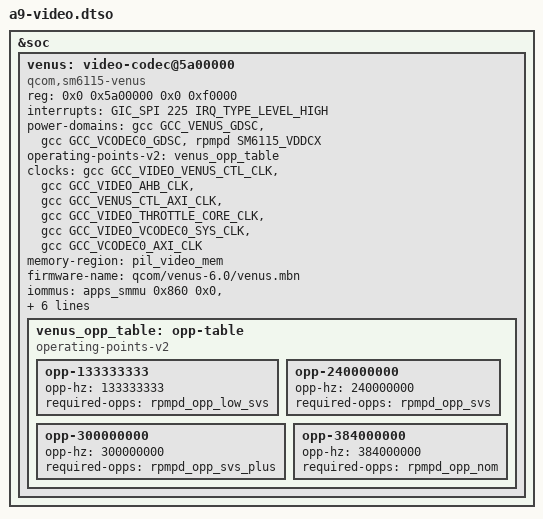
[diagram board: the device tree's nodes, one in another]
// SPDX-License-Identifier: (GPL-2.0-only OR BSD-2-Clause)
/dts-v1/;
/plugin/;
#include <dt-bindings/clock/qcom,gcc-sm6115.h>
#include <dt-bindings/interrupt-controller/arm-gic.h>
#include <dt-bindings/interconnect/qcom,sm6115.h>
#include <dt-bindings/interconnect/qcom,rpm-icc.h>
#include <dt-bindings/power/qcom-rpmpd.h>

/* SM6115 node from Dmitry Baryshkov's upstream series, 2026-05-15.
 * Use existing Venus AR50_LITE / HFI4 support through the schema's QCM2290
 * fallback. R4 has no video node. Do not change the existing video carveout.
 */
&soc {
	venus: video-codec@5a00000 {
		compatible = "qcom,sm6115-venus", "qcom,qcm2290-venus";
		reg = <0x0 0x5a00000 0x0 0xf0000>;
		interrupts = <GIC_SPI 225 IRQ_TYPE_LEVEL_HIGH>;
		power-domains = <&gcc GCC_VENUS_GDSC>,
				<&gcc GCC_VCODEC0_GDSC>, <&rpmpd SM6115_VDDCX>;
		power-domain-names = "venus", "vcodec0", "cx";
		operating-points-v2 = <&venus_opp_table>;
		clocks = <&gcc GCC_VIDEO_VENUS_CTL_CLK>, <&gcc GCC_VIDEO_AHB_CLK>,
			 <&gcc GCC_VENUS_CTL_AXI_CLK>, <&gcc GCC_VIDEO_THROTTLE_CORE_CLK>,
			 <&gcc GCC_VIDEO_VCODEC0_SYS_CLK>, <&gcc GCC_VCODEC0_AXI_CLK>;
		clock-names = "core", "iface", "bus", "throttle", "vcodec0_core", "vcodec0_bus";
		memory-region = <&pil_video_mem>;
		firmware-name = "qcom/venus-6.0/venus.mbn";
		iommus = <&apps_smmu 0x860 0x0>, <&apps_smmu 0x880 0x0>;
		interconnects = <&mmnrt_virt MASTER_VIDEO_P0 RPM_ALWAYS_TAG
				 &bimc SLAVE_EBI_CH0 RPM_ALWAYS_TAG>,
				<&bimc MASTER_AMPSS_M0 RPM_ACTIVE_TAG
				 &config_noc SLAVE_VENUS_CFG RPM_ACTIVE_TAG>;
		interconnect-names = "video-mem", "cpu-cfg";
		status = "okay";
		venus_opp_table: opp-table {
			compatible = "operating-points-v2";
			opp-133333333 {
				opp-hz = /bits/ 64 <133333333>;
				required-opps = <&rpmpd_opp_low_svs>;
			};
			opp-240000000 {
				opp-hz = /bits/ 64 <240000000>;
				required-opps = <&rpmpd_opp_svs>;
			};
			opp-300000000 {
				opp-hz = /bits/ 64 <300000000>;
				required-opps = <&rpmpd_opp_svs_plus>;
			};
			opp-384000000 {
				opp-hz = /bits/ 64 <384000000>;
				required-opps = <&rpmpd_opp_nom>;
			};
		};
	};
};
